# CC3220SF register map
Vendor: Texas Instruments; Series: Wireless Connectivity MCU; File version: 1
CPU: CM4 r1p0, little endian, no MPU, no FPU, 8 interrupt priority bits
Registers are 32-bit, read-write, reset 0x0 unless marked. A register's access mark holds for its fields unless they carry their own. Offsets are from the block's base; [hi:lo] are bit positions; {n}, {i} and the like mark numbered series.

## ADC
Base 0x4402E800
0x00 CTRL — ADC control register.
{0x4+4i} CH{i}_GAIN (i=0..7) — Channel {i} gain setting
{0x24+4i} CH{i}_IRQ_EN (i=0..7) — Channel {i} interrupt enable register
0x44 CH0_IRQ_STATUS — Channel 0 interrupt status register
0x48 CH1_IRQ_STATUS — Channel 1 interrupt status register
0x4C CH2_IRQ_STATUS
0x50 CH3_IRQ_STATUS — Channel 3 interrupt status register
0x54 CH4_IRQ_STATUS — Channel 4 interrupt status register
0x58 CH5_IRQ_STATUS
0x5C CH6_IRQ_STATUS — Channel 6 interrupt status register
0x60 CH7_IRQ_STATUS — Channel 7 interrupt status register
0x64 DMA_MODE_EN — DMA mode enable register
0x68 TIMER_CONFIGURATION — ADC timer configuration register
0x70 TIMER_CURRENT_COUNT — ADC timer current count register
{0x74+4i} CHANNEL{i}FIFODATA (i=0..7) — CH{i} FIFO DATA register
0x94 CH0_FIFO_LVL — channel 0 FIFO Level register
0x98 CH1_FIFO_LVL — Channel 1 interrupt status register
0x9C CH2_FIFO_LVL
0xA0 CH3_FIFO_LVL — Channel 3 interrupt status register
0xA4 CH4_FIFO_LVL — Channel 4 interrupt status register
0xA8 CH5_FIFO_LVL
0xAC CH6_FIFO_LVL — Channel 6 interrupt status register
0xB0 CH7_FIFO_LVL — Channel 7 interrupt status register
0xB8 CH_ENABLE

## DTHE
Base 0x44030000
0x810 SHA_IM
0x814 SHA_RIS
0x818 SHA_MIS
0x81C SHA_IC
0x820 AES_IM
0x824 AES_RIS
0x828 AES_MIS
0x82C AES_IC
0x830 DES_IM
0x834 DES_RIS
0x838 DES_MIS
0x83C DES_IC
0xA00 EIP_CGCFG
0xA04 EIP_CGREQ
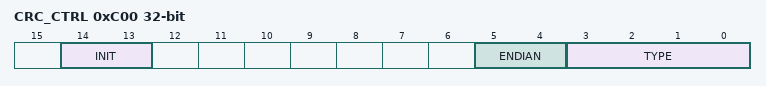
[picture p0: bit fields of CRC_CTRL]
0xC00 CRC_CTRL
  [14:13] INIT — Initialize the CRC 00 use SEED register context as starting value 10 all zero? 11 all one? This is self clearing. With first write to data register this value clears to zero and remain zero for rest of the operation unless written again
  [5:4] ENDIAN — Endian control [0] swap byte in half-word [1] swap half word
  [3:0] TYPE — Type of operation 0000 polynomial 0x8005 0001 polynomial 0x1021 0010 polynomial 0x4C11DB7 0011 polynomial 0x1EDC6F41 1000 TCP checksum TYPE in DTHE_S_CRC_CTRL & DTHE_S_CRC_CTRL should be exclusive
0xC10 CRC_SEED
0xC14 CRC_DIN
0xC18 CRC_RSLT_PP
{0xF00+4i} RAND_KEY{i} (i=0..3)

## DES
Base 0x44039000
0x00 KEY3_L — KEY3 (LSW) for 192-bit key
0x04 KEY3_H — KEY3 (MSW) for 192-bit key
0x08 KEY2_L — KEY2 (LSW) for 192-bit key
0x0C KEY2_H — KEY2 (MSW) for 192-bit key
0x10 KEY1_L — KEY1 (LSW) for 128-bit key/192-bit key
0x14 KEY1_H — KEY1 (LSW) for 128-bit key/192-bit key
0x18 IV_L — Initialization vector LSW
0x1C IV_H — Initialization vector MSW
0x20 CTRL
  [5:4] MODE — Select CBC ECB or CFB mode 0x0 ecb mode 0x1 cbc mode 0x2 cfb mode 0x3 reserved
0x24 LENGTH — Indicates the cryptographic data length in bytes for all modes. Once processing is started with this context this length decrements to zero. Data lengths up to (2^32 1) bytes are allowed. A write to this register triggers the engine to start using this context. For a Host read operation these registers return all-zeroes.
0x28 DATA_L — Data register(LSW) to read/write encrypted/decrypted data.
0x2C DATA_H — Data register(MSW) to read/write encrypted/decrypted data.
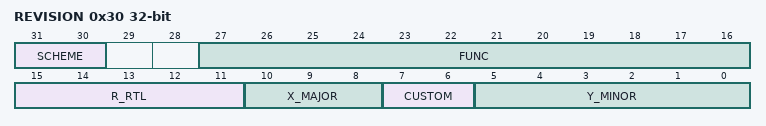
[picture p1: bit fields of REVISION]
0x30 REVISION
  [31:30] SCHEME
  [27:16] FUNC — Function indicates a software compatible module family. If there is no level of software compatibility a new Func number (and hence REVISION) should be assigned.
  [15:11] R_RTL — RTL Version (R) maintained by IP design owner. RTL follows a numbering such as X.Y.R.Z which are explained in this table. R changes ONLY when: (1) PDS uploads occur which may have been due to spec changes (2) Bug fixes occur (3) Resets to '0' when X or Y changes. Design team has an internal 'Z' (customer invisible) number which increments on every drop that happens due to DV and RTL updates. Z resets to 0 when R increments.
  [10:8] X_MAJOR — Major Revision (X) maintained by IP specification owner. X changes ONLY when: (1) There is a major feature addition. An example would be adding Master Mode to Utopia Level2. The Func field (or Class/Type in old PID format) will remain the same. X does NOT change due to: (1) Bug fixes (2) Change in feature parameters.
  [7:6] CUSTOM
  [5:0] Y_MINOR — Minor Revision (Y) maintained by IP specification owner. Y changes ONLY when: (1) Features are scaled (up or down). Flexibility exists in that this feature scalability may either be represented in the Y change or a specific register in the IP that indicates which features are exactly available. (2) When feature creeps from Is-Not list to Is list. But this may not be the case once it sees silicon; in which case X will change. Y does NOT change due to: (1) Bug fixes (2) Typos or clarifications (3) major functional/feature change/addition/deletion. Instead these changes may be reflected via R S X as applicable. Spec owner maintains a customer-invisible number 'S' which changes due to: (1) Typos/clarifications (2) Bug documentation. Note that this bug is not due to a spec change but due to implementation. Nevertheless the spec tracks the IP bugs. An RTL release (say for silicon PG1.1) that occurs due to bug fix should document the corresponding spec number (X.Y.S) in its release notes.
0x34 SYSCONFIG
0x38 SYSSTATUS
0x3C IRQSTATUS — This register indicates the interrupt status. If one of the interrupt bits is set the interrupt output will be asserted
0x40 IRQENABLE — This register contains an enable bit for each unique interrupt generated by the module. It matches the layout of DES_IRQSTATUS register. An interrupt is enabled when the bit in this register is set to 1 ****************************************************************************

## NVIC
Base 0xE000E000
0x04 INT_TYPE — Interrupt Controller Type Reg
0x08 ACTLR — Auxiliary Control
0x10 ST_CTRL — SysTick Control and Status Register
0x14 ST_RELOAD — SysTick Reload Value Register
0x18 ST_CURRENT — SysTick Current Value Register
0x1C ST_CAL — SysTick Calibration Value Reg
0x100 EN0 — Interrupt 0-31 Set Enable
0x104 EN1 — Interrupt 32-54 Set Enable
0x108 EN2 — Interrupt 64-95 Set Enable
0x10C EN3 — Interrupt 96-127 Set Enable
0x110 EN4 — Interrupt 128-131 Set Enable
0x114 EN5 — Interrupt 160-191 Set Enable
0x180 DIS0 — Interrupt 0-31 Clear Enable
0x184 DIS1 — Interrupt 32-54 Clear Enable
0x188 DIS2 — Interrupt 64-95 Clear Enable
0x18C DIS3 — Interrupt 96-127 Clear Enable
0x190 DIS4 — Interrupt 128-131 Clear Enable
0x194 DIS5 — Interrupt 160-191 Clear Enable
0x200 PEND0 — Interrupt 0-31 Set Pending
0x204 PEND1 — Interrupt 32-54 Set Pending
0x208 PEND2 — Interrupt 64-95 Set Pending
0x20C PEND3 — Interrupt 96-127 Set Pending
0x210 PEND4 — Interrupt 128-131 Set Pending
0x214 PEND5 — Interrupt 160-191 Set Pending
0x280 UNPEND0 — Interrupt 0-31 Clear Pending
0x284 UNPEND1 — Interrupt 32-54 Clear Pending
0x288 UNPEND2 — Interrupt 64-95 Clear Pending
0x28C UNPEND3 — Interrupt 96-127 Clear Pending
0x290 UNPEND4 — Interrupt 128-131 Clear Pending
0x294 UNPEND5 — Interrupt 160-191 Clear Pending
0x300 ACTIVE0 — Interrupt 0-31 Active Bit
0x304 ACTIVE1 — Interrupt 32-54 Active Bit
0x308 ACTIVE2 — Interrupt 64-95 Active Bit
0x30C ACTIVE3 — Interrupt 96-127 Active Bit
0x310 ACTIVE4 — Interrupt 128-131 Active Bit
0x314 ACTIVE5 — Interrupt 160-191 Active Bit
{0x400+4i} PRI{i} (i=0..12) — Interrupt {4i}-{4i+3} Priority
0x434 PRI13 — Interrupt 52-53 Priority
{0x400+4i} PRI{i} (i=14..48) — Interrupt {4i}-{4i+3} Priority
0xD00 CPUID — CPU ID Base
0xD04 INT_CTRL — Interrupt Control and State
0xD08 VTABLE — Vector Table Offset
0xD0C APINT — Application Interrupt and Reset Control
0xD10 SYS_CTRL — System Control
0xD14 CFG_CTRL — Configuration and Control
{0xD14+4i} SYS_PRI{i} (i=1..3) — System Handler Priority {i}
0xD24 SYS_HND_CTRL — System Handler Control and State
0xD28 FAULT_STAT — Configurable Fault Status
0xD2C HFAULT_STAT — Hard Fault Status
0xD30 DEBUG_STAT — Debug Status Register
0xD34 MM_ADDR — Memory Management Fault Address
0xD38 FAULT_ADDR — Bus Fault Address
0xD90 MPU_TYPE
0xD94 MPU_CTRL — MPU Control
0xD98 MPU_NUMBER — MPU Region Number
0xD9C MPU_BASE — MPU Region Base Address
0xDA0 MPU_ATTR — MPU Region Attribute and Size
{0xD9C+8i} MPU_BASE{i} (i=1..3) — MPU Region Base Address Alias {i}
{0xDA0+8i} MPU_ATTR{i} (i=1..3) — MPU Region Attribute and Size Alias {i}
0xDF0 DBG_CTRL — Debug Control and Status Reg
0xDF4 DBG_XFER — Debug Core Reg. Transfer Select
0xDF8 DBG_DATA — Debug Core Register Data
0xDFC DBG_INT — Debug Reset Interrupt Control
0xF00 SW_TRIG — Software Trigger Interrupt ***************************************************************************
